# ATSAMRH707F18A register map
Vendor: Microchip Technology; Series: SAMRH707; File version: 0
CPU: CM7 r1p1, little endian, MPU, FPU, 3 interrupt priority bits
Registers are 32-bit, read-write, reset 0x0 unless marked. A register's access mark holds for its fields unless they carry their own. Offsets are from the block's base; [hi:lo] are bit positions; lines under a group give offsets from that group; {n}, {i} and the like mark numbered series; 'fields as' and 'values as' point back to an identical list.

## HSMC — Harden Static Memory Controller
Base 0x40081000; register names take the prefix HSMC_
{0x0+0x10*i} HSMC_CS[{i}] (i=0..1) group
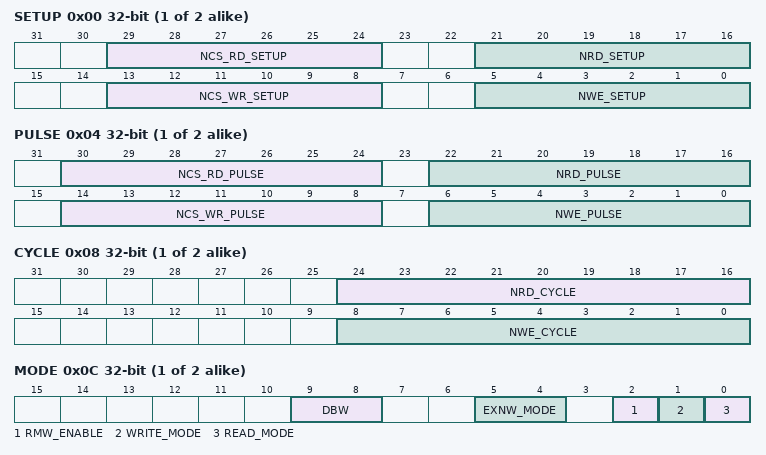
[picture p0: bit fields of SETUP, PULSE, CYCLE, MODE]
  0x00 SETUP — HSMC Setup Register
    [29:24] NCS_RD_SETUP — NCS Setup Length in READ Access
    [21:16] NRD_SETUP — NRD Setup Length
    [13:8] NCS_WR_SETUP — NCS Setup Length in WRITE Access
    [5:0] NWE_SETUP — NWE Setup Length
  0x04 PULSE — HSMC Pulse Register
    [30:24] NCS_RD_PULSE — NCS Pulse Length in READ Access
    [22:16] NRD_PULSE — NRD Pulse Length
    [14:8] NCS_WR_PULSE — NCS Pulse Length in WRITE Access
    [6:0] NWE_PULSE — NWE Pulse Length
  0x08 CYCLE — HSMC Cycle Register
    [24:16] NRD_CYCLE — Total Read Cycle Length
    [8:0] NWE_CYCLE — Total Write Cycle Length
  0x0C MODE — HSMC Mode Register
    [9:8] DBW — Data Bus Width
      0=_8_BIT (8-bit Data Bus)
    [5:4] EXNW_MODE — NWAIT Mode
      0=DISABLED (Disabled-The NWAIT input signal is ignored on the corresponding chip select.); 2=FROZEN (Frozen Mode-If asserted, the NWAIT signal freezes the current read or write cycle. After deassertion, the read/write cycle is resumed from the point where it was stopped.); 3=READY (Ready Mode-The NWAIT signal indicates the availability of the external device at the end of the pulse of the controlling read or write signal, to complete the access. If high, the access normally completes. If low, the access is extended until NWAIT returns high.)
    [2] RMW_ENABLE — Read-Modify Write enable
    [1] WRITE_MODE
    [0] READ_MODE
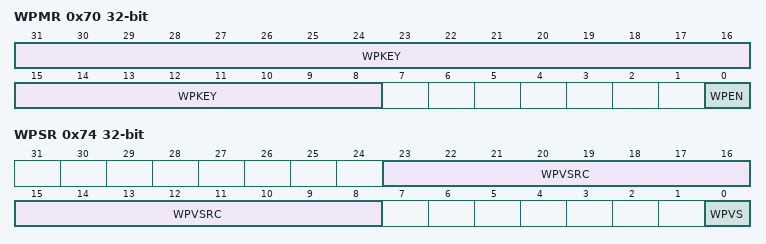
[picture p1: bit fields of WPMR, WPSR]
0x70 WPMR — HSMC Write Protection Mode Register
  [31:8] WPKEY — Write Protection Key
    0x534D43=PASSWD (Writing any other value in this field aborts the write operation of the WPEN bit. Always reads as 0.)
  [0] WPEN — Write Protect Enable
0x74 WPSR ro — HSMC Write Protection Status Register
  [23:8] WPVSRC — Write Protection Violation Source
  [0] WPVS — Write Protection Violation Status

## IP1553
Base 0x4003C000; register names take the prefix IP1553_
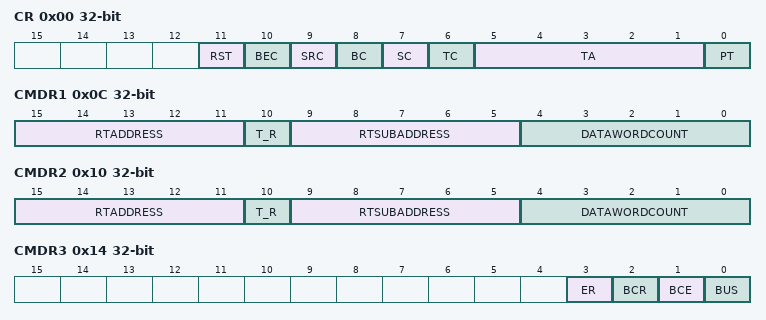
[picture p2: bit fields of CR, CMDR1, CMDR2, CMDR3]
0x00 CR — Configuration Register
  [11] RST — Soft Reset
  [10] BEC — BCEnableCmd
  [9] SRC — SREQBitCmd
  [8] BC — BusyBitCmd
  [7] SC — SSBitCmd
  [6] TC — TRBitCmd
  [5:1] TA — TermAddressConf
  [0] PT — POTermConf
0x0C CMDR1 wo — Command Register 1
  [15:11] RTADDRESS, [10] T_R, [9:5] RTSUBADDRESS, [4:0] DATAWORDCOUNT
0x10 CMDR2 wo — Command Register 2
  [15:11] RTADDRESS
  [10] T_R — R/T
  [9:5] RTSUBADDRESS
  [4:0] DATAWORDCOUNT
0x14 CMDR3 wo — Command Register 3
  [3] ER — data or command transfer
  [2] BCR — 1553 receiver
  [1] BCE — 1553 emitter
  [0] BUS — bus used
0x18 BITR wo — BIT Register
  [15:0] TOBITWORD
0x1C VWR wo — Vector Word Register
  [15:0] TOVECTORWORD
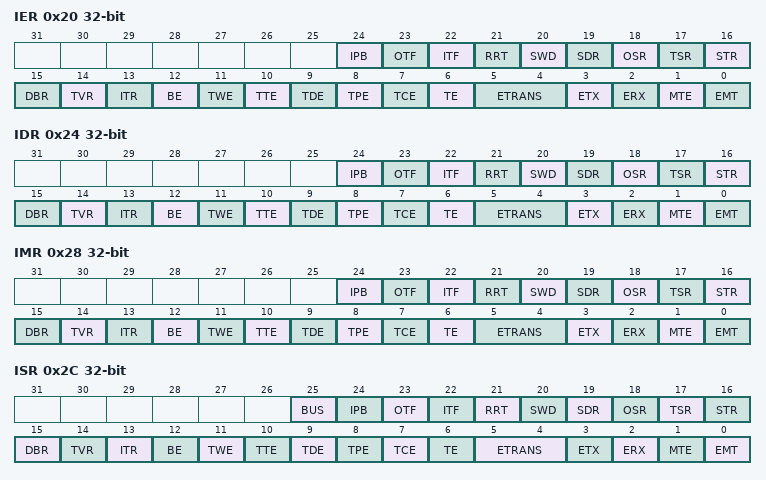
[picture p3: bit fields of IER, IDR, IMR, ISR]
0x20 IER wo — IRQ Mask Enable Register
  [24] IPB — IPBusy
  [23] OTF — OvInhibitTermFlagReq
  [22] ITF — InhibitTermFlagReq
  [21] RRT — ResetRTReq
  [20] SWD — SyncWithoutDataReq
  [19] SDR — SyncWithDataReq
  [18] OSR — OvTranShutdownReq
  [17] TSR — TranShutdownReq
  [16] STR — InitSelfTestReq
  [15] DBR — DynamicBusContReq
  [14] TVR — TransVecWordReq
  [13] ITR — IllegalTransferReq
  [12] BE — BufIFErr
  [11] TWE — TransWordCounterErr
  [10] TTE — TransTimeOutErr
  [9] TDE — TransDataTypeErr
  [8] TPE — TransParityErr
  [7] TCE — TransCodingErr
  [6] TE — TransErr
  [5:4] ETRANS — EndTransfer
  [3] ETX — EndTransmission
  [2] ERX — End reception
  [1] MTE — MemTransferErr
  [0] EMT — EndMemTransfer
0x24 IDR wo — IRQ Mask Disable Register
  fields as IER
0x28 IMR ro — IRQ Mask Register
  fields as IER
0x2C ISR ro — IRQ Status Register
  [25] BUS — BUS activated on last transfer
  [24] IPB — IPBusy
  [23] OTF — OvInhibitTermFlagReq
  [22] ITF — InhibitTermFlagReq
  [21] RRT — ResetRTReq
  [20] SWD — SyncWithoutDataReq
  [19] SDR — SyncWithDataReq
  [18] OSR — OvTranShutdownReq
  [17] TSR — TranShutdownReq
  [16] STR — InitSelfTestReq
  [15] DBR — DynamicBusContReq
  [14] TVR — TransVecWordReq
  [13] ITR — IllegalTransferReq
  [12] BE — BufIFErr
  [11] TWE — TransWordCounterErr
  [10] TTE — TransTimeOutErr
  [9] TDE — TransDataTypeErr
  [8] TPE — TransParityErr
  [7] TCE — TransCodingErr
  [6] TE — TransErr
  [5:4] ETRANS — EndTransfer
  [3] ETX — EndTransmission
  [2] ERX — End reception
  [1] MTE — MemTransferErr
  [0] EMT — EndMemTransfer
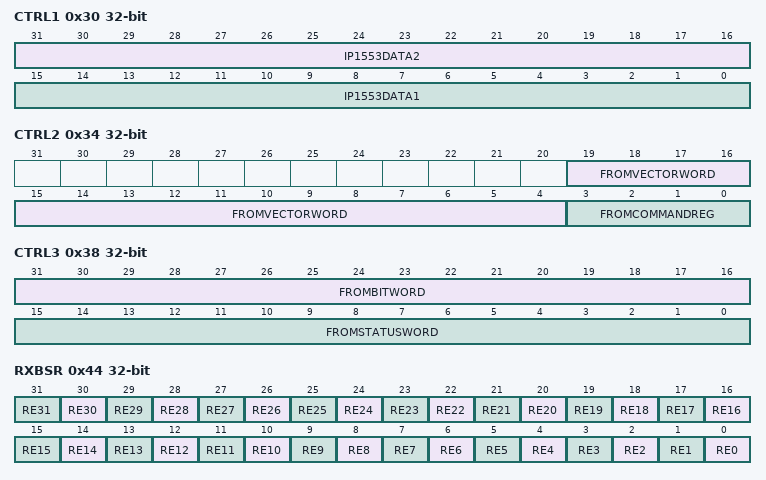
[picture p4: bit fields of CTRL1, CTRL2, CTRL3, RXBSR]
0x30 CTRL1 ro — Control Register 1
  [31:16] IP1553DATA2 — IP1553 data value 2
  [15:0] IP1553DATA1 — IP1553 data value 1
0x34 CTRL2 ro — Control Register 2
  [19:4] FROMVECTORWORD — from vector register
  [3:0] FROMCOMMANDREG — from command register
0x38 CTRL3 ro — Control Register 3
  [31:16] FROMBITWORD — content of bit word register
  [15:0] FROMSTATUSWORD — content of status word register
0x3C ARW — Address Register Write
  [31:0] REG_ADDR_APB_W — TX base address
0x40 ARR — Address Register Read
  [31:0] REG_ADDR_APB_R — RX base address
0x44 RXBSR — Rx Buffer Status Register
  [n] RE{n} (n=0..31) — Receive Buffer, {n} with x=[0-31]
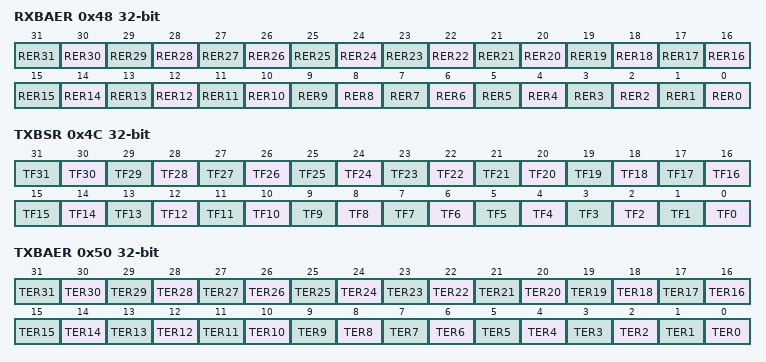
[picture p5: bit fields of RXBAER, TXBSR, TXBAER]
0x48 RXBAER — Rx Buffer Access Error Register
  [n] RER{n} (n=0..31) — Receive error {n}, x with x=[0-31]
0x4C TXBSR — Tx Buffer Status Register
  [n] TF{n} (n=0..31) — Transmit buffer {n}, x with x=[0-31]
0x50 TXBAER — Tx Buffer Access Error Register
  [n] TER{n} (n=0..31) — Transmit error {n}, x with x=[0-31]

## Notices in the file
Copyright (c) 2017 Microchip Technology Inc.
SPDX-License-Identifier: Apache-2.0
Licensed under the Apache License, Version 2.0 (the "License");
you may not use this file except in compliance with the License.
You may obtain a copy of the License at
http://www.apache.org/licenses/LICENSE-2.0
Unless required by applicable law or agreed to in writing, software
distributed under the License is distributed on an "AS IS" BASIS,
WITHOUT WARRANTIES OR CONDITIONS OF ANY KIND, either express or implied.
See the License for the specific language governing permissions and
limitations under the License.
